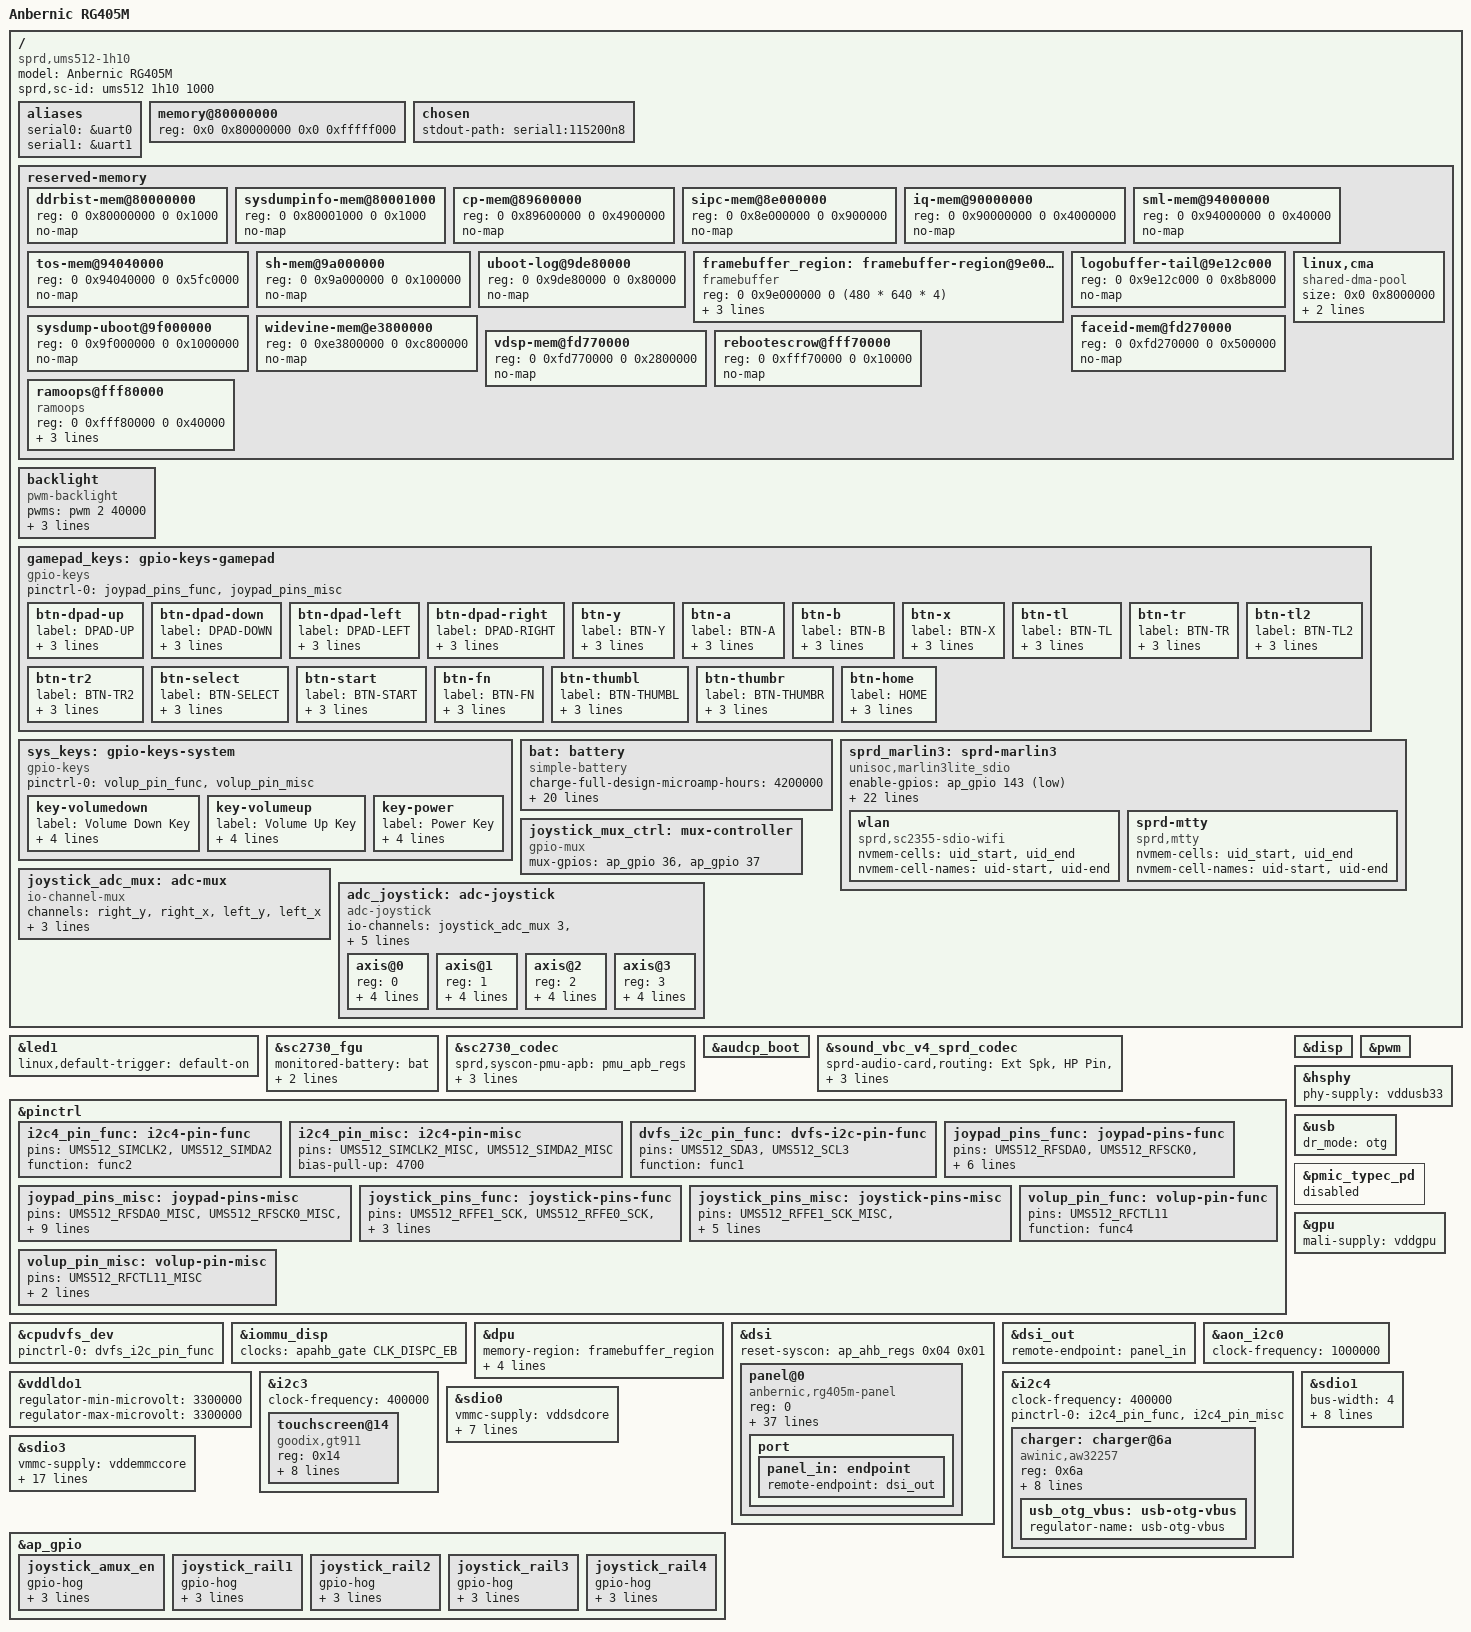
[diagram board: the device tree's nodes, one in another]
// SPDX-License-Identifier: (GPL-2.0 OR MIT)
/*
 * Anbernic RG405M (Unisoc UMS512 / T618, sharkl5pro) board DTS.
 *
 * Derived from ums512-rg-rotate.dts (same SoC, same board family
 * ums512_1h10). RG405M deltas vs RG Rotate, all confirmed against the
 * stock DTB/DTBO dumps (device-extract/):
 *   - 640x480 MIPI panel (ST7701S-class, 2 lanes), reset ap_gpio 50,
 *     avdd+avee share ap_gpio 16
 *   - 4 GiB DRAM (stock: reg 0xfffff000)
 *   - GT911 touch on i2c3 @0x14, irq ap_gpio 144, reset ap_gpio 145,
 *     vdd = PMIC vddldo1 (stock phandle 0x121 = LDO_VDDLDO1)
 *   - gamepad: 17 buttons + Fn on GPIO (same alt-func pads as Rotate);
 *     dual analog sticks via singleadc-joypad (ADC ch2 + amux) — driver
 *     port pending, see docs/HARDWARE-ANALYSIS.md
 *   - no hall sensor / swivel
 *   - Wi-Fi wakeup gpio 32 (Rotate: 33)
 */

/dts-v1/;

#include <dt-bindings/gpio/gpio.h>
#include <dt-bindings/input/input.h>
#include <dt-bindings/input/gpio-keys.h>
#include <dt-bindings/clock/sprd,ums512-clk.h>
#include <dt-bindings/mfd/sprd,sc2730-regs.h>
#include <dt-bindings/mfd/sprd,sc2730-mask.h>
#include "ums512.dtsi"
#include "sc2730.dtsi"
#include "sprd-sound-fe-be.dtsi"

/ {
	model = "Anbernic RG405M";
	compatible = "sprd,ums512-1h10", "sprd,ums512";
	sprd,sc-id = "ums512 1h10 1000";

	aliases {
		serial0 = &uart0;
		serial1 = &uart1;
	};

	memory@80000000 {
		device_type = "memory";
		reg = <0x0 0x80000000 0x0 0xfffff000>;
	};

	chosen {
		#address-cells = <2>;
		#size-cells = <2>;
		stdout-path = "serial1:115200n8";
	};

	reserved-memory {
		#address-cells = <2>;
		#size-cells = <2>;
		ranges;

		/*
		 * ddrbist + sysdumpinfo: the first two pages of DRAM. u-boot
		 * and the sysdump machinery stamp magic values here across
		 * reboots.
		 */
		ddrbist-mem@80000000 {
			reg = <0 0x80000000 0 0x1000>;
			no-map;
		};

		sysdumpinfo-mem@80001000 {
			reg = <0 0x80001000 0 0x1000>;
			no-map;
		};

		/* Modem CP image + CP/AP SIPC shared memory. The CP is not
		 * started under mainline, but stock reserves both and the
		 * boot chain may still touch them - keep them out of the
		 * allocator. */
		cp-mem@89600000 {
			reg = <0 0x89600000 0 0x4900000>;
			no-map;
		};

		sipc-mem@8e000000 {
			reg = <0 0x8e000000 0 0x900000>;
			no-map;
		};

		/* Stock base DT reserves this 64MB IQ/calibration buffer but
		 * frees it at runtime outside calibration mode. Reserved
		 * while hunting corruption; candidate to reclaim later. */
		iq-mem@90000000 {
			reg = <0 0x90000000 0 0x4000000>;
			no-map;
		};

		sml-mem@94000000 {
			reg = <0 0x94000000 0 0x40000>;
			no-map;
		};

		tos-mem@94040000 {
			reg = <0 0x94040000 0 0x5fc0000>;
			no-map;
		};

		sh-mem@9a000000 {
			reg = <0 0x9a000000 0 0x100000>;
			no-map;
		};

		/* u-boot console log capture (read back via pstore/ramoops
		 * tooling); u-boot writes here unconditionally. */
		uboot-log@9de80000 {
			reg = <0 0x9de80000 0 0x80000>;
			no-map;
		};

		framebuffer_region: framebuffer-region@9e000000 {
			compatible = "framebuffer";
			reg = <0 0x9e000000 0 (480 * 640 * 4)>;
			iommu-addresses = <&dpu 0x9e000000 (480 * 640 * 4)>;
			no-map;
		};

		/* Remainder of stock's logobuffer@9e000000 (0x9e4000 total);
		 * the framebuffer node above only covers the panel-sized
		 * slice u-boot actually scans out. */
		logobuffer-tail@9e12c000 {
			reg = <0 0x9e12c000 0 0x8b8000>;
			no-map;
		};

		/* Stock base DT reserves 16MB here for u-boot sysdump; the
		 * live tree shows it zero-sized because u-boot rewrites the
		 * node, but the region may still be stamped by the boot
		 * chain. Reserved while hunting corruption. */
		sysdump-uboot@9f000000 {
			reg = <0 0x9f000000 0 0x1000000>;
			no-map;
		};

		/*
		 * Secure/DRM pool. Stock declares this in a devicetree
		 * overlay (fragment@11) rather than the base dts. The secure
		 * world writes this region whether or not the kernel knows
		 * about it - leaving it unreserved corrupts the page
		 * allocator once allocations reach 0xe3800000.
		 */
		widevine-mem@e3800000 {
			reg = <0 0xe3800000 0 0xc800000>;
			no-map;
		};

		/* Camera faceid + vDSP firmware regions. High DRAM - if left
		 * unreserved these are exactly where big allocations (page
		 * cache on large files) start landing and getting corrupted. */
		faceid-mem@fd270000 {
			reg = <0 0xfd270000 0 0x500000>;
			no-map;
		};

		vdsp-mem@fd770000 {
			reg = <0 0xfd770000 0 0x2800000>;
			no-map;
		};

		rebootescrow@fff70000 {
			reg = <0 0xfff70000 0 0x10000>;
			no-map;
		};

		/* Persistent kernel console/oops log, same layout as stock so
		 * u-boot's uboot_log dumper keeps working. No no-map: ramoops
		 * needs to map it. */
		ramoops@fff80000 {
			compatible = "ramoops";
			reg = <0 0xfff80000 0 0x40000>;
			record-size = <0x8000>;
			console-size = <0x8000>;
			pmsg-size = <0x8000>;
		};

		linux,cma {
			compatible = "shared-dma-pool";
			size = <0x0 0x8000000>;
			reusable;
			linux,cma-default;
		};
	};

	/* v7-proven backlight: stock PWM2, 40000 ns period, 64/255 default. */
	backlight: backlight {
		compatible = "pwm-backlight";
		pwms = <&pwm 2 40000>;
		brightness-levels = <0 16 32 48 64 80 96 112 128 144 160 176 192 208 224 240 255>;
		default-brightness-level = <4>;
	};

	/*
	 * RG405M panel power: v7-proven — the stock DT declares NO panel
	 * supply/GPIO (avdd/avee ride an always-on PMIC LDO). The panel keeps
	 * the bootloader's power state; we must not claim ap_gpio 16 here or
	 * risk toggling a rail the panel already depends on. (Research §12.)
	 */

	/*
	 * Gamepad buttons. Pad mapping decoded from the stock DTBO
	 * singleadc-joypad node + the u-boot gpio_fun_pin[] table
	 * (src/u-boot board/spreadtrum/ums512_1h10/gpio_pin.c):
	 *   dedicated GPIO pads (work as-is): 86, 87, 88, 116
	 *   alt-func pads needing func4 muxing: the RF, KEYIN, SPI2,
	 *   MEMS_MIC and IIS3 ones below.
	 * The two analog sticks live in the stock singleadc-joypad node
	 * (ADC ch2 behind a 4-way gpio amux); their driver port is still
	 * pending - tracked in docs/HARDWARE-ANALYSIS.md.
	 */
	gamepad_keys: gpio-keys-gamepad {
		compatible = "gpio-keys";
		pinctrl-names = "default";
		pinctrl-0 = <&joypad_pins_func &joypad_pins_misc>;

		btn-dpad-up {
			label = "DPAD-UP";
			linux,code = <BTN_DPAD_UP>;
			gpios = <&ap_gpio 26 GPIO_ACTIVE_LOW>;	/* RFCTL7 */
			debounce-interval = <2>;
		};
		btn-dpad-down {
			label = "DPAD-DOWN";
			linux,code = <BTN_DPAD_DOWN>;
			gpios = <&ap_gpio 25 GPIO_ACTIVE_LOW>;	/* RFCTL6 */
			debounce-interval = <2>;
		};
		btn-dpad-left {
			label = "DPAD-LEFT";
			linux,code = <BTN_DPAD_LEFT>;
			gpios = <&ap_gpio 97 GPIO_ACTIVE_LOW>;	/* MEMS_MIC_DATA1 */
			debounce-interval = <2>;
		};
		btn-dpad-right {
			label = "DPAD-RIGHT";
			linux,code = <BTN_DPAD_RIGHT>;
			gpios = <&ap_gpio 86 GPIO_ACTIVE_LOW>;	/* GPIO86 */
			debounce-interval = <2>;
		};
		/*
		 * Face buttons: GPIO numbers verified identical to stock
		 * vendor.dts (sw5-sw8), but the ROTATE reference mapped the
		 * BTN_* codes differently and on-device evtest proved the
		 * physical positions on the RG405M are:
		 *   west = GPIO116, east = GPIO113, south = GPIO112,
		 *   north = GPIO88.
		 * Codes are assigned by physical position (what emulators
		 * expect); letters follow the Nintendo-style print.
		 */
		btn-y {					/* physical west */
			label = "BTN-Y";
			linux,code = <BTN_WEST>;
			gpios = <&ap_gpio 116 GPIO_ACTIVE_LOW>;	/* GPIO116 */
			debounce-interval = <2>;
		};
		btn-a {					/* physical east */
			label = "BTN-A";
			linux,code = <BTN_EAST>;
			gpios = <&ap_gpio 113 GPIO_ACTIVE_LOW>;	/* IIS3DO */
			debounce-interval = <2>;
		};
		btn-b {					/* physical south */
			label = "BTN-B";
			linux,code = <BTN_SOUTH>;
			gpios = <&ap_gpio 112 GPIO_ACTIVE_LOW>;	/* IIS3DI */
			debounce-interval = <2>;
		};
		btn-x {					/* physical north */
			label = "BTN-X";
			linux,code = <BTN_NORTH>;
			gpios = <&ap_gpio 88 GPIO_ACTIVE_LOW>;	/* GPIO88 */
			debounce-interval = <2>;
		};
		btn-tl {
			label = "BTN-TL";
			linux,code = <BTN_TL>;
			gpios = <&ap_gpio 14 GPIO_ACTIVE_LOW>;	/* RFSEN1 */
			debounce-interval = <2>;
		};
		btn-tr {
			label = "BTN-TR";
			linux,code = <BTN_TR>;
			gpios = <&ap_gpio 1 GPIO_ACTIVE_LOW>;	/* RFSDA0 */
			debounce-interval = <2>;
		};
		btn-tl2 {
			label = "BTN-TL2";
			linux,code = <BTN_TL2>;
			gpios = <&ap_gpio 3 GPIO_ACTIVE_LOW>;	/* RFSEN0 */
			debounce-interval = <2>;
		};
		btn-tr2 {
			label = "BTN-TR2";
			linux,code = <BTN_TR2>;
			gpios = <&ap_gpio 2 GPIO_ACTIVE_LOW>;	/* RFSCK0 */
			debounce-interval = <2>;
		};
		btn-select {
			label = "BTN-SELECT";
			linux,code = <BTN_SELECT>;
			gpios = <&ap_gpio 55 GPIO_ACTIVE_LOW>;	/* SPI2_CLK */
			debounce-interval = <2>;
		};
		btn-start {
			label = "BTN-START";
			linux,code = <BTN_START>;
			gpios = <&ap_gpio 87 GPIO_ACTIVE_LOW>;	/* GPIO87 */
			debounce-interval = <2>;
		};
		btn-fn {
			label = "BTN-FN";
			linux,code = <BTN_MODE>;
			gpios = <&ap_gpio 126 GPIO_ACTIVE_LOW>;	/* KEYIN2 */
			debounce-interval = <2>;
		};
		btn-thumbl {
			label = "BTN-THUMBL";
			linux,code = <BTN_THUMBL>;
			gpios = <&ap_gpio 20 GPIO_ACTIVE_LOW>;	/* RFCTL1 */
			debounce-interval = <2>;
		};
		btn-thumbr {
			label = "BTN-THUMBR";
			linux,code = <BTN_THUMBR>;
			gpios = <&ap_gpio 23 GPIO_ACTIVE_LOW>;	/* RFCTL4 */
			debounce-interval = <2>;
		};
		/*
		 * The F button. Stock vendor.dts calls GPIO124 "GPIO BACK KEY"
		 * with KEY_BACK; it was mistakenly mapped to BTN_SELECT here
		 * (duplicate of the real Select on GPIO55 — evtest confirmed).
		 * KEY_HOMEPAGE fits Linux launcher semantics better than
		 * Android's BACK; change to KEY_BACK if frontends prefer it.
		 */
		btn-home {
			label = "HOME";
			linux,code = <KEY_HOMEPAGE>;
			gpios = <&ap_gpio 124 GPIO_ACTIVE_LOW>;	/* KEYIN0 */
			debounce-interval = <2>;
		};
	};

	sys_keys: gpio-keys-system {
		compatible = "gpio-keys";
		pinctrl-names = "default";
		pinctrl-0 = <&volup_pin_func &volup_pin_misc>;

		key-volumedown {
			label = "Volume Down Key";
			linux,code = <KEY_VOLUMEDOWN>;
			gpios = <&pmic_eic 4 GPIO_ACTIVE_HIGH>;
			debounce-interval = <2>;
			wakeup-source;
		};
		key-volumeup {
			label = "Volume Up Key";
			linux,code = <KEY_VOLUMEUP>;
			gpios = <&ap_gpio 30 GPIO_ACTIVE_LOW>;	/* RFCTL11 */
			debounce-interval = <2>;
			wakeup-source;
		};
		key-power {
			label = "Power Key";
			linux,code = <KEY_POWER>;
			gpios = <&pmic_eic 1 GPIO_ACTIVE_LOW>;
			debounce-interval = <2>;
			wakeup-source;
		};
	};

	bat: battery {
		compatible = "simple-battery";
		charge-full-design-microamp-hours = <4200000>;
		charge-term-current-microamp = <120000>;
		constant-charge-voltage-max-microvolt = <4300000>;
		factory-internal-resistance-micro-ohms = <130000>;
		voltage-min-design-microvolt = <3410000>;
		operating-range-celsius = <0 60>;
		ocv-capacity-celsius = <25>;
		ocv-capacity-table-0 =
			<4292000 100>, <4184000 95>, <4118000 90>,
			<4046000 85>, <3989000 80>, <3934000 75>,
			<3881000 70>, <3821000 65>, <3775000 60>,
			<3729000 55>, <3685000 50>, <3656000 45>,
			<3639000 40>, <3625000 35>, <3608000 30>,
			<3589000 25>, <3563000 20>, <3533000 15>,
			<3493000 10>, <3448000 5>, <3400000 0>;
		voltage-temp-table =
			<1095000 800>, <986000 850>, <878000 900>, <775000 950>,
			<678000 1000>, <590000 1050>, <510000 1100>, <440000 1150>,
			<378000 1200>, <324000 1250>, <278000 1300>, <238000 1350>,
			<204000 1400>, <175000 1450>, <150000 1500>, <129000 1550>,
			<111000 1600>, <96000 1650>;
	};
};

&led1 {
	linux,default-trigger = "default-on";
};

&sc2730_fgu {
	status = "okay";
	monitored-battery = <&bat>;
	power-supplies = <&charger>;
	sprd,calib-resistance-micro-ohms = <10000>;
};

&sc2730_codec {
	status = "okay";
	sprd,syscon-pmu-apb = <&pmu_apb_regs>;
	hp-use-inter-pa = <1>;
	fixed-sample-rate = <48000 48000 48000>;
	digital-codec = <&sprd_audio_codec_dig>;
};

&audcp_boot {
	status = "okay";
};

&sound_vbc_v4_sprd_codec {
	status = "okay";
	sprd-audio-card,routing =
		"Ext Spk", "HP Pin",
		"Ext Spk1", "HP Pin";
	sprd,spk-ext-pa-info = <0 0 4 0>;
	sprd,spk-ext-pa-gpio = <&ap_gpio 9 1>;
};

&pinctrl {
	i2c4_pin_func: i2c4-pin-func {
		pins = "UMS512_SIMCLK2", "UMS512_SIMDA2";
		function = "func2";
	};

	i2c4_pin_misc: i2c4-pin-misc {
		pins = "UMS512_SIMCLK2_MISC", "UMS512_SIMDA2_MISC";
		/* 4700 => WPUS|WPU, matching the u-boot pinmap (strong pull for
		 * the open-drain i2c lines). */
		bias-pull-up = <4700>;
	};

	/*
	 * SDA3/SCL3 carry the TOP-DVFS engine's autonomous I2C channel to
	 * the FAN53555 (DCDC_CPU1); func1 like every other real I2C pad.
	 */
	dvfs_i2c_pin_func: dvfs-i2c-pin-func {
		pins = "UMS512_SDA3", "UMS512_SCL3";
		function = "func1";
	};

	/*
	 * Gamepad buttons on alt-func pads (RF*, SPI2_CLK, MEMS_MIC_DATA1,
	 * IIS3D*, KEYIN*). Pad<->line mapping from the u-boot gpio_fun_pin[]
	 * table; func4 muxing + pull-ups, same mechanism as RG Rotate.
	 */
	joypad_pins_func: joypad-pins-func {
		pins = "UMS512_RFSDA0", "UMS512_RFSCK0", "UMS512_RFSEN0",
		       "UMS512_RFSEN1", "UMS512_RFCTL1", "UMS512_RFCTL4",
		       "UMS512_RFCTL6", "UMS512_RFCTL7", "UMS512_SPI2_CLK",
		       "UMS512_MEMS_MIC_DATA1", "UMS512_IIS3DI",
		       "UMS512_IIS3DO", "UMS512_KEYIN0", "UMS512_KEYIN2";
		function = "func4";
	};

	joypad_pins_misc: joypad-pins-misc {
		pins = "UMS512_RFSDA0_MISC", "UMS512_RFSCK0_MISC",
		       "UMS512_RFSEN0_MISC", "UMS512_RFSEN1_MISC",
		       "UMS512_RFCTL1_MISC", "UMS512_RFCTL4_MISC",
		       "UMS512_RFCTL6_MISC", "UMS512_RFCTL7_MISC",
		       "UMS512_SPI2_CLK_MISC", "UMS512_MEMS_MIC_DATA1_MISC",
		       "UMS512_IIS3DI_MISC", "UMS512_IIS3DO_MISC",
		       "UMS512_KEYIN0_MISC", "UMS512_KEYIN2_MISC";
		input-enable;
		bias-pull-up = <20000>;
	};

	/*
	 * Analog stick plumbing (stock singleadc-joypad):
	 *   gpio15 (RFFE1_SCK)  = amux enable
	 *   gpio36/37 (RFFE0_SCK/SDA) = amux select A/B
	 *   gpio19/21/22/24 (RFCTL0/2/3/5) = per-axis sensor power rails
	 * All are control outputs; func4 = GPIO on this SoC, same mechanism
	 * as the buttons above.
	 */
	joystick_pins_func: joystick-pins-func {
		pins = "UMS512_RFFE1_SCK", "UMS512_RFFE0_SCK",
		       "UMS512_RFFE0_SDA", "UMS512_RFCTL0",
		       "UMS512_RFCTL2", "UMS512_RFCTL3", "UMS512_RFCTL5";
		function = "func4";
	};

	joystick_pins_misc: joystick-pins-misc {
		pins = "UMS512_RFFE1_SCK_MISC", "UMS512_RFFE0_SCK_MISC",
		       "UMS512_RFFE0_SDA_MISC", "UMS512_RFCTL0_MISC",
		       "UMS512_RFCTL2_MISC", "UMS512_RFCTL3_MISC",
		       "UMS512_RFCTL5_MISC";
		/* driven outputs: kill any residual pad pulls (an empty node
		 * would parse to zero pinmaps and warn "no valid maps"). */
		bias-disable;
	};

	volup_pin_func: volup-pin-func {
		pins = "UMS512_RFCTL11";
		function = "func4";
	};

	volup_pin_misc: volup-pin-misc {
		pins = "UMS512_RFCTL11_MISC";
		input-enable;
		bias-pull-up = <20000>;
	};
};

&cpudvfs_dev {
	status = "okay";
	pinctrl-names = "default";
	pinctrl-0 = <&dvfs_i2c_pin_func>;
};

/*
 * Display: v7-proven configuration (build/v7/ums512-rg405m-diag.dts, pipeline
 * "rg405m-pixel-clock-v6" — panel lit on hardware). Deltas vs the earlier
 * in-house version, all of them from the hardware-proven v7 tree:
 *   - iommu_disp gets the DISPC AP AHB gate clock explicitly (register access
 *     shares it; without it a probe-time MMIO can wedge the bus → dead console)
 *   - dpu pins CLK_DISPC0_DPI to pll2/128 MHz ÷ 5 = 25.6 MHz: boot firmware
 *     leaves DPHY selector 5, which is absent from Linux's parent table
 *   - panel uses compatible "anbernic,rg405m-panel" → the patched
 *     panel-generic-dsi runs the stock init sequence verbatim (it already
 *     contains sleep-out/display-on with vendor delays) and skips its own
 *   - seq=… wait=… payloads with the ORIGINAL per-command waits (0x11 → 200 ms,
 *     0x29 → 10 ms), regenerated from the stock sprd,initial-command blob by
 *     build/v7/prepare_display.py; delays=5,50,120,10,10
 *   - rotation = <90>: physical panel is portrait 480x640, enclosure landscape
 *     (u-boot banner renders portrait for the same reason)
 *   - no vdd/iovcc supplies: stock DT declares none (panel is powered from an
 *     always-on rail; bootloader state must be preserved)
 */
&iommu_disp {
	status = "okay";
	/* Register access shares the DPU AP AHB gate; do not rely on U-Boot
	 * or the as-yet-unloaded display driver to have enabled it. */
	clocks = <&apahb_gate CLK_DISPC_EB>;
};

&disp {
	status = "okay";
};

&dpu {
	status = "okay";
	memory-region = <&framebuffer_region>;
	reset-syscon = <&ap_ahb_regs 0x04 0x02>;
	/* Boot firmware left DPHY selector 5, absent from Linux's parent table.
	 * Use the stock panel's 128 MHz / 5 = 25.6 MHz path explicitly. */
	assigned-clocks = <&ap_clk CLK_DISPC0_DPI>;
	assigned-clock-parents = <&pll2 CLK_TWPLL_128M>;
	assigned-clock-rates = <25600000>;
};

&pwm {
	status = "okay";
};

&dsi {
	status = "okay";
	reset-syscon = <&ap_ahb_regs 0x04 0x01>;

	#address-cells = <1>;
	#size-cells = <0>;

	panel@0 {
		compatible = "anbernic,rg405m-panel";
		reg = <0>;
		reset-gpios = <&ap_gpio 50 GPIO_ACTIVE_LOW>;
		/* Physical panel is portrait 480x640; enclosure is landscape. */
		rotation = <90>;
		backlight = <&backlight>;
		panel_description =
			"G lanes=2 format=rgb888 size=109,62 flags=3 hs_rate=368000000 lp_rate=20000000 delays=5,50,120,10,10",
			"M clock=25600 horizontal=480,54,50,50 vertical=640,10,13,10 default=1",
			"I seq=ff7701000013 wait=0",
			"I seq=ef08 wait=0",
			"I seq=ff7701000010 wait=0",
			"I seq=c04f03 wait=0",
			"I seq=c10c02 wait=0",
			"I seq=c21006 wait=0",
			"I seq=c704 wait=0",
			"I seq=cc38 wait=0",
			"I seq=b040161d0e12060c0a09250003003f3f1c wait=0",
			"I seq=b140161e0e11060c0809260015003f3f1c wait=0",
			"I seq=ff7701000011 wait=0",
			"I seq=b04d wait=0",
			"I seq=b135 wait=0",
			"I seq=b207 wait=0",
			"I seq=b380 wait=0",
			"I seq=b547 wait=0",
			"I seq=b785 wait=0",
			"I seq=b820 wait=0",
			"I seq=b910 wait=0",
			"I seq=bc03 wait=0",
			"I seq=c089 wait=0",
			"I seq=c178 wait=0",
			"I seq=c278 wait=0",
			"I seq=d088 wait=0",
			"I seq=e0000002 wait=0",
			"I seq=e10400000005000000002020 wait=0",
			"I seq=e200000000000000000000000000 wait=0",
			"I seq=e300003300 wait=0",
			"I seq=e42200 wait=0",
			"I seq=e5045ca0a0065ca0a00000000000000000 wait=0",
			"I seq=e600003300 wait=0",
			"I seq=e72200 wait=0",
			"I seq=e8055ca0a0075ca0a00000000000000000 wait=0",
			"I seq=eb02004040000000 wait=0",
			"I seq=ec0000 wait=0",
			"I seq=edfa450bffffffffffffffffffffb054af wait=0",
			"I seq=ef080808453f54 wait=0",
			"I seq=ff7701000000 wait=0",
			"I seq=3617 wait=0",
			"I seq=3a77 wait=0",
			"I seq=11 wait=c8",
			"I seq=29 wait=a";

		port {
			panel_in: endpoint {
				remote-endpoint = <&dsi_out>;
			};
		};
	};
};

&dsi_out {
	remote-endpoint = <&panel_in>;
};

/*
 * First-boot diagnostic posture: mirror the v7-proven USB wiring. TCPM
 * (pmic_typec_pd) is disabled — its sc27xx typec driver is NOT in this kernel
 * build — so the role never flips and the g_serial gadget never binds (no COM
 * port). v7 forces role=device from init via the usb_role class sysfs and
 * this was proven to enumerate on the RG405M.
 */
&hsphy {
	status = "okay";
	phy-supply = <&vddusb33>;
};

&usb {
	status = "okay";
	dr_mode = "otg";
};

&pmic_typec_pd {
	status = "disabled";
};

&gpu {
	mali-supply = <&vddgpu>;
	status = "okay";
};

/*
 * Stock enables the hw-i2c master at 1MHz (overlay fragment@12 on aon_i2c0).
 * The big cluster's DVFS voltage path runs through it.
 */
&aon_i2c0 {
	status = "okay";
	clock-frequency = <1000000>;
};

/*
 * vddldo1 is the shared 3.3 V rail for the touch controller (stock:
 * touch node vdd-supply = <0x121>, vdd-voltage = 0x325aa0 = 3.3 V) and the
 * joypad analog rails (same supply, same voltage in stock). The mainline
 * goodix driver only ENABLES its supplies, never sets voltage — without a
 * pinned constraint the LDO can come up at its 1.2 V floor and the GT911
 * never ACKs I2C (observed: probe -EIO on 0x8140). Pin to stock's 3.3 V.
 */
&vddldo1 {
	regulator-min-microvolt = <3300000>;
	regulator-max-microvolt = <3300000>;
};

/*
 * GT911 touchscreen on i2c3 @0x14 (stock: i2c@600000 / touchscreen@14).
 * Same chip and gpios as RG Rotate (irq 144 / reset 145, ACTIVE_HIGH —
 * the mainline goodix driver writes literal levels through the reset/INT
 * handshake that selects the 0x14 address, so ACTIVE_LOW inverts it and
 * every transaction fails with -EIO).
 * Touch vdd is PMIC LDO1 pinned to 3.3 V above (stock vdd-voltage 0x325aa0).
 * Scanout is portrait 480x640 while the handheld is landscape; start with
 * both axes inverted like the Rotate and verify with evtest on device.
 */
&i2c3 {
	status = "okay";
	clock-frequency = <400000>;
	#address-cells = <1>;
	#size-cells = <0>;

	touchscreen@14 {
		compatible = "goodix,gt911";
		reg = <0x14>;
		AVDD28-supply = <&vddldo1>;
		VDDIO-supply = <&vddldo1>;
		irq-gpios = <&ap_gpio 144 GPIO_ACTIVE_HIGH>;
		reset-gpios = <&ap_gpio 145 GPIO_ACTIVE_HIGH>;
		touchscreen-size-x = <480>;
		touchscreen-size-y = <640>;
		touchscreen-inverted-x;
		touchscreen-inverted-y;
	};
};

&i2c4 {
	status = "okay";
	clock-frequency = <400000>;
	pinctrl-names = "default";
	pinctrl-0 = <&i2c4_pin_func &i2c4_pin_misc>;
	#address-cells = <1>;
	#size-cells = <0>;

	charger: charger@6a {
		compatible = "awinic,aw32257";
		reg = <0x6a>;
		monitored-battery = <&bat>;
		fuel-gauge = <&sc2730_fgu>;
		ti,current-limit = <1800>;
		ti,weak-battery-voltage = <3400>;
		ti,battery-regulation-voltage = <4300>;
		/*
		 * ~0.43C of the 4200 mAh pack, deliberately below stock's
		 * 2000 mA until proper JEITA thermal limiting exists.
		 */
		ti,charge-current = <1240>;
		ti,termination-current = <200>;
		ti,resistor-sense = <33>;

		usb_otg_vbus: usb-otg-vbus {
			regulator-name = "usb-otg-vbus";
		};
	};
};

/*
 * SD slot: v7-proven conservative settings. This board's SD is unstable when
 * the controller switches signaling to 1.8 V (stock kernel log: "signal
 * voltage enable hw fail" -> card removed). no-1-8-v + 25 MHz caps it at
 * high-speed 3.3 V; broken-cd treats the card as always present (the boot
 * rootfs lives on it — a spurious removal would be fatal).
 */
&sdio0 {
	status = "okay";
	vmmc-supply = <&vddsdcore>;
	vqmmc-supply = <&vddsdio>;
	bus-width = <4>;
	max-frequency = <25000000>;
	broken-cd;
	no-1-8-v;
	no-sdio;
	no-mmc;
};

&sdio3 {
	status = "okay";
	vmmc-supply = <&vddemmccore>;
	bus-width = <8>;
	voltage-ranges = <3000 3000>;
	non-removable;
	cap-mmc-hw-reset;
	sprd,phy-delay-mmc-hs400es = <0x40 0x7f 0x2d 0x2d>;
	sprd,phy-delay-mmc-hs400 = <0x3f 0xdf 0x2f 0x2f>;
	sprd,phy-delay-mmc-hs200 = <0x7f 0xde 0xd4 0xd4>;
	sprd,phy-delay-mmc-ddr52 = <0x3e 0x37 0x24 0x24>;
	sprd,phy-delay-mmc-highspeed = <0x60 0xb7 0x34 0x34>;
	mmc-hs400-enhanced-strobe;
	mmc-hs400-1_8v;
	mmc-hs200-1_8v;
	mmc-ddr-1_8v;
	no-sdio;
	no-sd;
};

&sdio1 {
	status = "okay";
	bus-width = <4>;
	sprd,phy-delay-sd-uhs-sdr104 = <0x7f 0x76 0x69 0x69>;
	sprd,phy-delay-sd-uhs-sdr50 = <0x7f 0xf7 0xf5 0xf5>;
	sd-uhs-sdr104;
	sd-uhs-sdr50;
	no-sd;
	no-mmc;
};

/ {
	sprd_marlin3: sprd-marlin3 {
		compatible = "unisoc,marlin3lite_sdio";
		enable-gpios = <&ap_gpio 143 GPIO_ACTIVE_LOW>;
		reset-gpios = <&ap_gpio 95 GPIO_ACTIVE_LOW>;
		m2-wakeup-ap-gpios = <&ap_gpio 32 GPIO_ACTIVE_LOW>;
		m2-to-ap-irq-gpios = <&ap_gpio 94 GPIO_ACTIVE_LOW>;
		adma-tx;
		adma-rx;

		clock-names = "clk_32k", "source", "enable";
		clocks = <&aon_clk CLK_AUX0>, <&ext_32k>,
			 <&aonapb_gate CLK_AUX0_EB>;

		extcon = <&sdio1>;
		sdhci-name = <&sdio1>;

		sprd,btwf-file-name = "/lib/firmware/wcnmodem.bin";
		sprd,gnss-file-name = "/lib/firmware/gnssmodem.bin";

		avdd12-supply = <&vddwcn>;
		avdd33-supply = <&vddwifipa>;
		dcxo18-supply = <&vddsim2>;

		avdd12-parent-bound-chip = <REG_ANA_SLP_DCDC_PD_CTRL MASK_ANA_SLP_DCDCGEN1_PD_EN 0x0 MASK_ANA_SLP_DCDCGEN1_PD_EN>;
		avdd12-bound-wbreq = <REG_ANA_LDO_XTL_EN10 MASK_ANA_LDO_VDDWCN_EXT_XTL3_EN 0x0 MASK_ANA_LDO_VDDWCN_EXT_XTL3_EN>;
		avdd33-bound-wbreq = <REG_ANA_LDO_XTL_EN11 MASK_ANA_LDO_VDDWIFIPA_EXT_XTL3_EN 0x0 MASK_ANA_LDO_VDDWIFIPA_EXT_XTL3_EN>;

		wlan {
			compatible = "sprd,sc2355-sdio-wifi";
			nvmem-cells = <&uid_start>, <&uid_end>;
			nvmem-cell-names = "uid-start", "uid-end";
		};
		sprd-mtty {
			compatible = "sprd,mtty";
			nvmem-cells = <&uid_start>, <&uid_end>;
			nvmem-cell-names = "uid-start", "uid-end";
		};
	};

	/*
	 * Hall analog sticks (stock singleadc-joypad): ONE PMIC ADC channel
	 * (io-channels = <&pmic_adc 2>) behind a 4:1 analog mux selected by
	 * gpio36/37 (A/B) and enabled by gpio15; each axis has its own
	 * sensor-power rail (gpio19/21/22/24 = adc-power-ctl1..4).
	 *
	 * Upstream has no singleadc-joypad driver; compose from mainline
	 * pieces exactly like sun50i-h700-anbernic-rg35xx-h does:
	 * gpio-mux -> io-channel-mux -> adc-joystick.
	 *
	 * Simplification vs stock: the vendor driver powers one axis rail at
	 * a time (it also powers the sticks off when idle to save battery).
	 * Here all four rails + mux enable are hogged high permanently; the
	 * mux still selects the axis, so readings stay correct — we just lose
	 * the idle power saving. Channel order (left_x, left_y, right_x,
	 * right_y) matches amux-count=4 stock layout and rg35xx convention;
	 * verify with evtest and swap labels if the axes come out crossed.
	 */
	joystick_mux_ctrl: mux-controller {
		compatible = "gpio-mux";
		#mux-control-cells = <0>;
		/*
		 * amux-a (gpio36) = select bit0, amux-b (gpio37) = select bit1.
		 * Declared ACTIVE_HIGH so gpio-mux drives the same PHYSICAL
		 * levels the on-device sweep validated (state s -> A=s&1,B=s>>1).
		 */
		mux-gpios = <&ap_gpio 36 GPIO_ACTIVE_HIGH>,	/* amux-a */
			    <&ap_gpio 37 GPIO_ACTIVE_HIGH>;	/* amux-b */
	};

	joystick_adc_mux: adc-mux {
		compatible = "io-channel-mux";
		#io-channel-cells = <1>;
		/*
		 * Mux state -> axis, measured on device (user evtest report
		 * 2026-10-01): state0 = RIGHT stick vertical, state1 = RIGHT
		 * horizontal, state2 = LEFT vertical, state3 = LEFT horizontal.
		 */
		channels = "right_y", "right_x", "left_y", "left_x";
		io-channels = <&pmic_adc 2>;		/* stock joypad_adc */
		io-channel-names = "parent";
		mux-controls = <&joystick_mux_ctrl>;
		settle-time-us = <100>;
	};

	adc_joystick: adc-joystick {
		compatible = "adc-joystick";
		/*
		 * Axis mapping from on-device measurement: the adc-joystick
		 * axis@N reg N reads io-channels[N], so list the mux states in
		 * ABS order: X=left horizontal (state3), Y=left vertical
		 * (state2), RX=right horizontal (state1), RY=right vertical
		 * (state0).
		 */
		io-channels = <&joystick_adc_mux 3>,
			      <&joystick_adc_mux 2>,
			      <&joystick_adc_mux 1>,
			      <&joystick_adc_mux 0>;
		poll-interval = <5>;			/* stock poll-interval */
		/*
		 * func4 muxing for all seven stick lines (en/A/B + 4 rails).
		 * Attached here because this node probes last — after the
		 * gpio-hogs latched their output values in the GPIO block —
		 * so flipping the pads to GPIO drives the latched levels
		 * immediately. (rg35xx does the same with joy_mux_pin.)
		 */
		pinctrl-names = "default";
		pinctrl-0 = <&joystick_pins_func &joystick_pins_misc>;
		#address-cells = <1>;
		#size-cells = <0>;

		axis@0 {
			reg = <0>;
			linux,code = <ABS_X>;
			abs-range = <0 4095>;		/* 12-bit sc2730 ADC */
			abs-fuzz = <16>;
			abs-flat = <32>;
		};
		axis@1 {
			reg = <1>;
			linux,code = <ABS_Y>;
			abs-range = <0 4095>;
			abs-fuzz = <16>;
			abs-flat = <32>;
		};
		axis@2 {
			reg = <2>;
			linux,code = <ABS_RX>;
			abs-range = <0 4095>;
			abs-fuzz = <16>;
			abs-flat = <32>;
		};
		axis@3 {
			reg = <3>;
			linux,code = <ABS_RY>;
			abs-range = <0 4095>;
			abs-fuzz = <16>;
			abs-flat = <32>;
		};
	};
};

&ap_gpio {
	/*
	 * Stick rails + mux enable — levels from the on-device brute-force
	 * sweep (STICK.TXT, build/stickdiag/):
	 *   - rails (gpio19/21/22/24): physical HIGH powers all four axis
	 *     sensors (spread ~1100 mV wiggled vs ~100 mV at physical low).
	 *     The stock ACTIVE_LOW-looking flag refers to the vendor driver's
	 *     logical level; electrically they are simply active-high.
	 *   - amux-en (gpio15): physical LOW enables the analog switch
	 *     (classic EN-bar); physical high = output disconnected.
	 *   - mux select (gpio36/37): driven physically (ACTIVE_HIGH) so
	 *     state 0 = (A=0,B=0), 1 = (A=1,B=0), 2 = (A=0,B=1), 3 = (A=1,B=1),
	 *     matching the stock channel order.
	 * func4 pad muxing rides on the adc-joystick node (probes after the
	 * hogs latched their levels).
	 */
	joystick_amux_en {
		gpio-hog;
		gpios = <15 GPIO_ACTIVE_LOW>;
		output-high;
		line-name = "stick-amux-en";
	};
	joystick_rail1 {
		gpio-hog;
		gpios = <19 GPIO_ACTIVE_HIGH>;
		output-high;
		line-name = "stick-rail-x";
	};
	joystick_rail2 {
		gpio-hog;
		gpios = <21 GPIO_ACTIVE_HIGH>;
		output-high;
		line-name = "stick-rail-y";
	};
	joystick_rail3 {
		gpio-hog;
		gpios = <22 GPIO_ACTIVE_HIGH>;
		output-high;
		line-name = "stick-rail-rx";
	};
	joystick_rail4 {
		gpio-hog;
		gpios = <24 GPIO_ACTIVE_HIGH>;
		output-high;
		line-name = "stick-rail-ry";
	};
};
